# YTM32B1ME1 register map
Vendor: YTMicro; File version: 1.0
CPU: CM33 r0p4, little endian, MPU, FPU, 2 interrupt priority bits
Registers are 32-bit, read-write, reset 0x0 unless marked. A register's access mark holds for its fields unless they carry their own. Offsets are from the block's base; [hi:lo] are bit positions; lines under a group give offsets from that group; {n}, {i} and the like mark numbered series; 'fields as' and 'values as' point back to an identical list.

## CAN0 (part 2 of 4) — FlexCAN module
Base 0x400D0000; register names take the prefix CAN0_
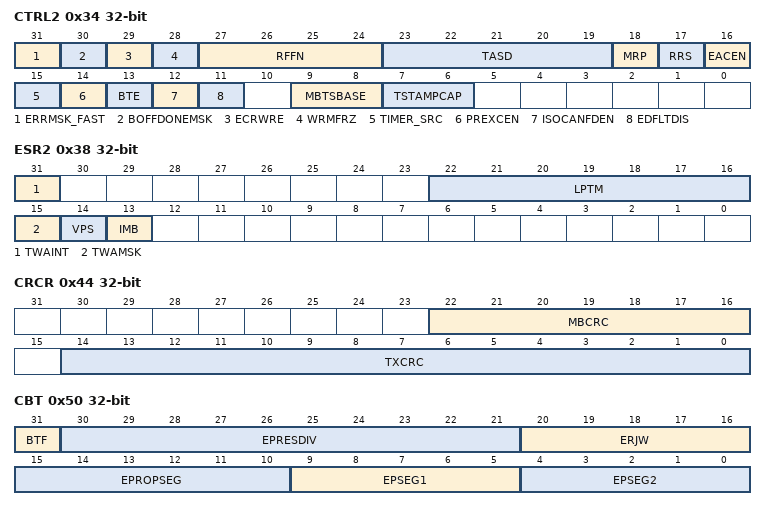
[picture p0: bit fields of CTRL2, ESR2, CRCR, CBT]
0x34 CTRL2
  [31] ERRMSK_FAST — ERRMSK_FAST provides a mask for the ERRINT_FAST Interrupt in CAN_ESR1. ERRMASK_FAST is not available (reserved, write 0) if parameter FD_EN is 0.
    0=ERRINT_FAST error interrupt disabled; 1=ERRINT_FAST error interrupt enabled
  [30] BOFFDONEMSK — Provides a mask for the Bus Off done interrupt in CAN_ESR1.
    0=Bus Off done interrupt disabled; 1=Bus Off done interrupt enabled
  [29] ECRWRE — ECRWRE is automatically set to 0 if the protocol described in section \hyperref[detection-and-correction-of-memory-errors]{"Detection and Correction of Memory Errors"} is not followed. ECRWRE is not available (reserved, write 0) if parameter ECC_EN is 0.
    0=Disable update; 1=Enable update
  [28] WRMFRZ — WRMFRZ can only be written in Freeze mode and has no effect out of Freeze mode. CAN_MCR.RFEN bit must not be set during FlexCAN memory initialization. WRMFRZ is not available (reserved, write 0) if parameter ECC_EN is 0.
    0=Maintain the write access restrictions; 1=Enable unrestricted write access to FlexCAN memory
  [27:24] RFFN — Number of Legacy Rx FIFO Filters – Defines the number of Legacy Rx FIFO filters. The maximum selectable number of filters is a function of configuration parameter NUMBER_OF_MB. RFFN must not be programmed with values that cause the number of message buffers occupied by Legacy Rx FIFO and ID Filter to exceed the number of mailboxes present, defined by CAN_MCR.MAXMB. Each group of eight filters occupies a memory space equivalent to two message buffers, which means that as more filters are implemented fewer mailboxes are available. Considering that the Legacy Rx FIFO occupies the memory space originally reserved for MB0–5, RFFN should be programmed with a value corresponding to a number of filters not greater than the number of available memory words, which can be calculated as follows: (SETUP_MB - 6) × 4 where SETUP_MB is the lower value between parameter NUMBER_OF_MB and register field CAN_MCR.MAXMB. The number of remaining mailboxes available will be: (SETUP_MB - 8) - (RFFN × 2) If the number of Legacy Rx FIFO filters programmed through RFFN exceeds the SETUP_MB value (memory space available), the exceeding ones will not be functional. NOTE: The number of the last remaining available mailbox is defined by the least value between (NUMBER_OF_MB - 1) and the CAN_MCR.MAXMB field. If Rx Individual Mask registers are not enabled, all Legacy Rx FIFO filters are affected by the Legacy Rx FIFO Global Mask. RFFN can only be written in Freeze mode as it is blocked by hardware in other modes.
  [23:19] TASD — TASD can be written only in Freeze mode because it is blocked by hardware in other modes. See \hyperref[tx-arbitration-start-delay]{"Tx Arbitration Start Delay"} for more details.
  [18] MRP — If MRP is set, the matching process starts from the mailboxes and if no match occurs the matching continues on the Legacy Rx FIFO. MRP can be written only in Freeze mode because it is blocked by hardware in other modes.
    0=Matching starts from Legacy Rx FIFO and continues on mailboxes; 1=Matching starts from mailboxes and continues on Legacy Rx FIFO
  [17] RRS — If RRS is asserted, a Remote Request Frame is submitted to a matching process and stored in the corresponding message buffer in the same fashion as a Data Frame. No automatic Remote Response Frame will be generated. If RRS is negated, the Remote Request Frame is submitted to a matching process and an automatic Remote Response Frame is generated if a message buffer with CODE=0b1010 is found with the same ID. RRS can be written only in Freeze mode because it is blocked by hardware in other modes.
    0=Remote Response Frame is generated; 1=Remote Request Frame is stored
  [16] EACEN — EACEN controls the comparison of IDE and RTR bits within Rx mailboxes filters with their corresponding bits in the incoming frame by the matching process. EACEN does not affect matching for Legacy Rx FIFO. EACEN can be written only in Freeze mode because it is blocked by hardware in other modes.
    0=Rx mailbox filter’s IDE bit is always compared and RTR is never compared, regardless of mask bits; 1=Enables the comparison of both the IDE and RTR bits of an Rx mailbox filter with the corresponding bits of the incoming frame. Mask bits do apply.
  [15] TIMER_SRC — TIMER_SRC can be written in Freeze mode only.
    0=The free-running timer is clocked by the CAN bit clock, which defines the baud rate on the CAN bus; 1=The free-running timer is clocked by an external time tick. The period can be either adjusted to be equal to the baud rate on the CAN bus or a different value as required.
  [14] PREXCEN — PREXCEN is writable only in Freeze mode. PREXCEN is not available (reserved, write 0) if parameter FE_EN is 0.
    0=Protocol exception is disabled; 1=Protocol exception is enabled
  [13] BTE — This field enables the use of the EPRS, EDCBT and ENCBT registers to configure the CAN bit timing segments, instead of using the bit timing fields of CBT, FDCBT, and CTRL1 registers. If CTRL2[BTE] is set: • PRESDIV, PROPSEG, PSEG1, PSEG2, and RJW fields in CTRL1 register are read as zero, and a write operation in them has no effect. • EPRESDIV, ERJW, EPROPSEG, EPSEG1, and EPSEG2 fields in the CBT register, and the FDCBT register, are read as zero and a write operation to them has no effect. • The ETDCOFF, ETDCEN, ETDCFAIL, and ETDCVAL fields of the ETDC register are used by FlexCAN instead of TDCOFF, TDCEN, TDCFAIL, and TDCVAL fields in FDCTRL register, which are read as zero, and a write operation in them has no effect. • ETDC[TDMDIS] can be used for disabling transceiver delay measurement.
    0=CAN Bit timing expansion is disabled; 1=CAN bit timing expansion is enabled
  [12] ISOCANFDEN — ISOCANFDEN enables ISO CAN FD compliant operation by enabling the following features, which are part of the ISO 11898 standard and not included in the original (Bosch) CAN FD protocol specification: • The count of variable stuff bits inserted from the Start of Frame bit to the last bit of Data field. Also, the modulo 8 count of variable stuff bits plus the respective parity bit (even parity calculated over the 3-bit modulo 8 count) are combined as the 4-bit Stuff Count field and inserted before the CRC Sequence field. • CRC calculation extends beyond the end of Data field and takes the Stuff Count field bits into account. ISOCANFDEN is writable only in Freeze mode. ISOCANFDEN is not available (reserved, write 0) if parameter FD_EN is 0.
    0=Disable ISO CAN FD specific features (non-ISO CAN FD operation); 1=Enable ISO CAN FD compliant operation
  [11] EDFLTDIS — When the edge filter is enabled, two consecutive nominal time quanta with dominant bus state are required to detect an edge that causes synchronization. When synchronization occurs, the counting of the sequence of eleven consecutive recessive bits is restarted. The edge filter prevents the dominant pulses that are shorter than a nominal bit time (present during the data phase of an FD Frame) from being mistaken for an idle condition. EDFLTDIS is writable only in Freeze mode. EDFLTDIS is not available (reserved, write 0) if parameter FD_EN is 0.
    0=Edge filter is enabled; 1=Edge filter is disabled
  [9:8] MBTSBASE — MBTSBASE selects which time base is used for capturing the 16-bit TIME STAMP field of the message buffer. MBTSBASE is writable only in Freeze mode. MBTSBASE is not available (reserved, write 0) if parameter TIME_STAMP_EN is 0.
    0=Message buffer time stamp base is CAN_TIMER; 1=Message buffer time stamp base is lower 16 bits of highresolution timer; 2=Message buffer time stamp base is upper 16 bits of high-resolution timer
  [7:6] TSTAMPCAP — TSTAMPCAP configures the point in time at which a 32-bit time base is captured during a CAN frame and stored in the highresolution time stamp register (CAN_HR_TIME_STAMPn). For Classical CAN frames, capture points can be the start of frame (SOF) bit or the point in time when a CAN frame is considered valid, which is the 7th bit of end of frame for transmission and the 6th bit of the end of frame for reception. For CAN FD frames, the high-resolution time stamp can be captured at SOF, the point in time when a CAN FD frame is considered valid, or the res bit. TSTAMPCAP is writable only in Freeze mode. TSTAMPCAP is not available (reserved, write 0) if parameter TIME_STAMP_EN is 0.
    0=The high-resolution time stamp capture is disabled; 1=The high-resolution time stamp is captured at the end of the CAN frame; 2=The high-resolution time stamp is captured at the start of the CAN frame; 3=The high-resolution time stamp is captured at the start of frame for classical CAN frames and at the res bit for CAN FD frames
0x38 ESR2 — The CAN_ESR2 register reports some general status information
  [31] TWAINT — TWAINT is set when the internal timer wraps around from 65535 to 0. If the corresponding mask bit (CAN_ESR2.TWAMSK) is set, an interrupt is generated to the CPU. TWAINT is cleared by writing 1 to it. Writing 0 has no effect. The TWAINT bit is not available (reserved, write 0) if parameter TIMER_WRAP_EN is 0.
    0=No such occurrence; 1=Timer wraparound has occurred
  [22:16] LPTM ro — If CAN_ESR2.VPS is asserted, LPTM indicates the lowest number inactive mailbox (see the CAN_ESR2.IMB bit description). If there is no inactive mailbox, then the mailbox indicated depends on the CAN_CTRL1.LBUF bit value: • If CAN_CTRL1.LBUF is negated, the mailbox indicated is the one that has the greatest arbitration value (see \hyperref[highest-priority-mailbox-first]{"Highest-Priority Mailbox First"} ). • If CAN_CTRL1.LBUF is asserted, the mailbox indicated is the highest number active Tx mailbox. If a Tx mailbox is being transmitted, it is not considered in LPTM calculation. If CAN_ESR2.IMB is not asserted and a frame is transmitted successfully, LPTM is updated with its mailbox number.
  [15] TWAMSK — Provides a mask for the Timer Wraparound interrupt (CAN_ESR2.TWAINT). The TWAMSK bit is not available (reserved, write 0) if parameter TIMER_WRAP_EN is 0.
    0=Timer Wraparound interrupt disabled; 1=Timer Wraparound interrupt enabled
  [14] VPS ro — VPS is asserted upon every complete Tx arbitration process unless the CPU writes to the C/S word of a mailbox that has already been scanned (is behind Tx Arbitration Pointer during the Tx arbitration process). If there is no inactive mailbox and only one Tx mailbox that is being transmitted, then VPS is not asserted. VPS is negated upon the start of every Tx arbitration process or upon a write to the C/S word of any mailbox. NOTE: VPS is not affected by any CPU write into the C/S of an MB that is blocked by the abort mechanism. When CAN_MCR.AEN is asserted, the abort code write into the C/S of an MB that is being transmitted (pending abort), or any write attempt into a Tx MB with CAN_IFLAG set is blocked.
    0=Contents of IMB and LPTM are invalid; 1=Contents of IMB and LPTM are valid
  [13] IMB ro — If CAN_ESR2.VPS is asserted, IMB indicates whether there is any inactive mailbox (CODE field is either 0b1000 or 0b0000). IMB is asserted in the following cases: • During arbitration, if a CAN_ESR2.LPTM is found and it is inactive. • If CAN_ESR2.IMB is not asserted and a frame is transmitted successfully. IMB is always cleared at start of arbitration (See \hyperref[arbitration-process]{"Arbitration Process"} ). NOTE: If an IMB is successfully transmitted and CAN_ESR2.IMB=0 (no inactive mailbox), then CAN_ESR2.VPS and CAN_ESR2.IMB are asserted and the index related to the MB just transmitted is loaded into CAN_ESR2.LPTM.
    0=If CAN_ESR2.VPS is asserted, CAN_ESR2.LPTM is not an inactive mailbox; 1=If CAN_ESR2.VPS is asserted, there is at least one inactive mailbox. CAN_ESR2.LPTM content is the number of the first one.
0x44 CRCR — The CAN_CRCR register provides information about the CRC of transmitted messages for non-FD messages. CAN_CRCR only reports the 15 low order bits of CRC calculations for messages in CAN FD format that require either 17 or 21 bits. For CAN FD format frames, the CAN_FDCRC register must be used. CAN_CRCR is updated at the same time the Tx interrupt flag is asserted. The CAN_FDCRC register is not available when parameter FD_EN is 0.
  [22:16] MBCRC ro — Indicates the number of the mailbox corresponding to the value in the CAN_CRCR.TXCRC field.
  [14:0] TXCRC ro — Indicates the CRC value of the last transmitted message for non-FD frames. For CAN FD frames, the CRC value is reported in CAN_FDCRC.
0x48 RXFGMASK
  [31:0] FGM — These bits mask the ID Filter Table elements bits in a perfect alignment. 0b - The corresponding bit in the filter is ``don't care". 1b - The corresponding bit in the filter is checked.
0x4C RXFIR — The CAN_RXFIR register provides information on the Legacy Rx FIFO. CAN_RXFIR is the port through which the CPU accesses the output of the RXFIR FIFO located in RAM. The RXFIR FIFO is written by the FlexCAN whenever a new message is moved into the Legacy Rx FIFO and its output is updated whenever the output of the Legacy Rx FIFO is updated with the next message. See \hyperref[legacy-rx-fifo]{"Legacy Rx FIFO"} for instructions on reading CAN_RXFIR.
  [8:0] IDHIT ro — Indicates which Identifier Acceptance Filter was hit by the received message that is in the output of the Legacy Rx FIFO. If multiple filters match the incoming message ID, the first matching IDAF found (lowest number) by the matching process is indicated. IDHIT is valid only when CAN_IFLAG1.BUF5I is asserted.
0x50 CBT — The CAN_CBT register is an alternative way to store the CAN bit timing variables described in the CAN_CTRL1 register. EPRESDIV, EPROPSEG, EPSEG1, EPSEG2, and ERJW are extended versions of CAN_CTRL1 register PRESDIV, PROPSEG, PSEG1, PSEG2, and RJW fields respectively. The BTF bit selects the use of the timing variables defined in CAN_CBT. The contents of CAN_CBT are not affected by soft reset. When CAN_CTRL2.BTE = 1, the EPRESDIV, ERJW, EPROPSEG, EPSEG1, and EPSEG2 fields in CAN_CBT are read as zero and a write operation to them has no effect. NOTE: The CAN bit variables in CAN_CTRL1 and in CAN_CBT are stored in the same register. NOTE: When the CAN FD feature is enabled (CAN_MCR.FDEN is set), always set $ ewline$ CAN_CBT.BTF.
  [31] BTF — BTF can be written in Freeze mode only.
    0=Extended bit time definitions disabled; 1=Extended bit time definitions enabled
  [30:21] EPRESDIV — When CAN_CBT.BTF is asserted, EPRESDIV defines the ratio between the PE clock frequency and the Serial Clock (Sclock) frequency. EPRESDIV extends the CAN_CTRL1.PRESDIV value range. Sclock frequency = PE clock frequency / (EPRESDIV + 1) The Sclock period defines the time quantum of the CAN protocol. For the reset value, the Sclock frequency is equal to the PE clock frequency (See \hyperref[protocol-timing]{"Protocol Timing"}). When CAN_CBT.BTF is negated, EPRESDIV has no effect. EPRESDIV can be written only in Freeze mode because it is blocked by hardware in other modes.
  [20:16] ERJW — When CAN_CBT.BTF is asserted, ERJW defines the maximum number of time quanta that a bit time can be changed by one resynchronization. ERJW extends the CAN_CTRL1.RJW value range. Resync Jump Width = ERJW + 1 One time quantum is equal to the Sclock period. When CAN_CBT.BTF is negated, ERJW has no effect. ERJW can be written only in Freeze mode because it is blocked by hardware in other modes.
  [15:10] EPROPSEG — When CAN_CBT.BTF is asserted, EPROPSEG defines the length of the Propagation Segment in the bit time. EPROPSEG extends the CAN_CTRL1.PROPSEG value range. Propagation Segment Time = (EPROPSEG + 1) × Time-Quanta Time-Quantum = one Sclock period When CAN_CBT.BTF is negated, EPROPSEG has no effect. EPROPSEG can be written only in Freeze mode because it is blocked by hardware in other modes.
  [9:5] EPSEG1 — When CAN_CBT.BTF is asserted, EPSEG1 defines the length of Phase Segment 1 in the bit time. EPSEG1 extends the CAN_CTRL1.PSEG1 value range. Phase Buffer Segment 1 = (EPSEG1 + 1) × Time-Quanta Time-Quantum = one Sclock period When CAN_CBT.BTF is negated, EPSEG1 has no effect. EPSEG1 can be written only in Freeze mode because it is blocked by hardware in other modes.
  [4:0] EPSEG2 — When CAN_CBT.BTF is asserted, EPSEG2 defines the length of Phase Segment 2 in the bit time. EPSEG2 extends the CAN_CTRL1.PSEG2 value range. Phase Buffer Segment 1 = (EPSEG2 + 1) × Time-Quanta Time-Quantum = one Sclock period When CAN_CBT.BTF is negated, EPSEG2 has no effect. EPSEG2 can be written only in Freeze mode because it is blocked by hardware in other modes.
0x68 IMASK4 — The CAN_IMASK4 register allows any number of the 32 message buffer interrupts to be enabled or disabled for MB127 to MB96. CAN_IMASK4 contains one interrupt mask bit per buffer, enabling the CPU to determine which buffer generates an interrupt after a successful transmission or reception (as indicated by the corresponding CAN_IFLAG4 bit). The CAN_IMASK4 register is not available if parameter NUMBER_OF_MB is less than 128.
  [31:0] BUF127TO96M — Each bit enables or disables the corresponding FlexCAN Message Buffer Interrupt for MB127 to MB96. When CAN FD is enabled, the MB range is defined according to the MBDSRn bit fields of the CAN_FDCTRL register. NOTE: Setting or clearing a bit in CAN_IMASK4 can assert or negate an interrupt request if the corresponding CAN_IFLAG4 bit is set. 0b - The corresponding buffer interrupt is disabled. 1b - The corresponding buffer interrupt is enabled.
0x6C IMASK3 — The CAN_IMASK3 register allows any number of the 32 message buffer interrupts to be enabled or disabled for MB95 to MB64. CAN_IMASK3 contains one interrupt mask bit per buffer, enabling the CPU to determine which buffer generates an interrupt after a successful transmission or reception (as indicated by the corresponding CAN_IFLAG3 bit). The CAN_IMASK3 register is not available if parameter NUMBER_OF_MB is less than 96.
  [31:0] BUF95TO64M — Each bit enables or disables the corresponding FlexCAN Message Buffer Interrupt for MB95 to MB64. When CAN FD is enabled, the MB range is defined according to the MBDSRn bit fields of the CAN_FDCTRL register. NOTE: Setting or clearing a bit in CAN_IMASK3 can assert or negate an interrupt request if the corresponding CAN_IFLAG3 bit is set. 0b - The corresponding buffer interrupt is disabled. 1b - The corresponding buffer interrupt is enabled.
0x70 IFLAG4 — The CAN_IFLAG4 register defines the flags for the 32 message buffer interrupts for MB127 to MB96. CAN_IFLAG4 contains one interrupt flag bit per buffer. Each successful transmission or reception sets the respective CAN_IFLAG4 bit. If the corresponding CAN_IMASK4 bit is set, an interrupt will be generated. The interrupt flag must be cleared by writing 1 to it. Writing 0 has no effect. Before updating the CAN_MCR.MAXMB field, the CPU must service the CAN_IFLAG4 bits whose MB value is greater than the CAN_MCR.MAXMB to be updated; otherwise, they will remain set and be inconsistent with the number of MBs available. The CAN_IFLAG4 register is not available if parameter NUMBER_OF_MB is less than 128.
  [31:0] BUF127TO96 — Each bit flags the corresponding FlexCAN Message Buffer Interrupt for MB127 to MB96. When CAN FD is enabled, the MB range is defined according to the MBDSRn bit fields of the CAN_FDCTRL register. 0b - The corresponding buffer has no occurrence of successfully completed transmission or reception. 1b - The corresponding buffer has successfully completed transmission or reception.
0x74 IFLAG3 — The CAN_IFLAG3 register defines the flags for the 32 Message Buffer interrupts for MB95 to MB64. CAN_IFLAG3 contains one interrupt flag bit per buffer. Each successful transmission or reception sets the respective CAN_IFLAG3 bit. If the corresponding CAN_IMASK3 bit is set, an interrupt will be generated. The interrupt flag must be cleared by writing 1 to it. Writing 0 has no effect. Before updating the CAN_MCR.MAXMB field, the CPU must service the CAN_IFLAG3 bits whose MB value is greater than the CAN_MCR.MAXMB to be updated; otherwise, they will remain set and be inconsistent with the number of MBs available. The CAN_IFLAG3 register is not available if parameter NUMBER_OF_MB is less than 96.
  [31:0] BUF95TO64 — Each bit flags the corresponding FlexCAN Message Buffer Interrupt for MB95 to MB64. When CAN FD is enabled, the MB range is defined according to the MBDSRn bit fields of the CAN_FDCTRL register. 0b - The corresponding buffer has no occurrence of successfully completed transmission or reception. 1b - The corresponding buffer has successfully completed transmission or reception.
{0x80+4i} RAM{i} (i=0..255)
  [31:0] RAM
0x880 RXIMR0 — The RX Individual Mask Registers are used to store the acceptance masks for ID filtering in Rx MBs and the Legacy Rx FIFO. When the Legacy Rx FIFO is disabled (CAN_MCR.RFEN is negated), an individual mask is provided for each available Rx mailbox on a one-to-one correspondence. When the Legacy Rx FIFO is enabled (CAN_MCR.RFEN is asserted), an individual mask is provided for each Legacy Rx FIFO ID Filter Table Element on a one-to-one correspondence depending on the setting of $ ewline$ CAN_CTRL2.RFFN (see \hyperref[legacy-rx-fifo]{"Legacy Rx FIFO"}). CAN_RXIMR0 stores the individual mask associated with either MB0 or ID Filter Table Element 0, CAN_RXIMR1 stores the individual mask associated with either MB1 or ID Filter Table Element 1, and so on. CAN_RXIMRn registers can only be accessed by the CPU when the FlexCAN is in Freeze mode; otherwise, they are blocked by hardware. The CAN_RXIMRn registers are not affected by reset. They are located in RAM and must be explicitly initialized prior to any reception. The CAN_RXIMRn registers are not available if parameter IRMQ_EN is 0.
  [31:0] MI — Each Individual Mask Bit masks the corresponding bit in both the mailbox filter and Legacy Rx FIFO ID Filter Table element in distinct ways. For mailbox filters, see the RXMGMASK register description. For Legacy Rx FIFO ID Filter Table elements, see the RXFGMASK register description. 0b - The corresponding bit in the filter is ``don't care". 1b - The corresponding bit in the filter is checked.
0x884 RXIMR1 — The RX Individual Mask Registers are used to store the acceptance masks for ID filtering in Rx MBs and the Legacy Rx FIFO. When the Legacy Rx FIFO is disabled (CAN_MCR.RFEN is negated), an individual mask is provided for each available Rx mailbox on a one-to-one correspondence. When the Legacy Rx FIFO is enabled (CAN_MCR.RFEN is asserted), an individual mask is provided for each Legacy Rx FIFO ID Filter Table Element on a one-to-one correspondence depending on the setting of $ ewline$ CAN_CTRL2.RFFN (see \hyperref[legacy-rx-fifo]{"Legacy Rx FIFO"}). CAN_RXIMR0 stores the individual mask associated with either MB0 or ID Filter Table Element 0, CAN_RXIMR1 stores the individual mask associated with either MB1 or ID Filter Table Element 1, and so on. CAN_RXIMRn registers can only be accessed by the CPU when the FlexCAN is in Freeze mode; otherwise, they are blocked by hardware. The CAN_RXIMRn registers are not affected by reset. They are located in RAM and must be explicitly initialized prior to any reception. The CAN_RXIMRn registers are not available if parameter IRMQ_EN is 0.
  fields as RXIMR0
0x888 RXIMR2 — The RX Individual Mask Registers are used to store the acceptance masks for ID filtering in Rx MBs and the Legacy Rx FIFO. When the Legacy Rx FIFO is disabled (CAN_MCR.RFEN is negated), an individual mask is provided for each available Rx mailbox on a one-to-one correspondence. When the Legacy Rx FIFO is enabled (CAN_MCR.RFEN is asserted), an individual mask is provided for each Legacy Rx FIFO ID Filter Table Element on a one-to-one correspondence depending on the setting of $ ewline$ CAN_CTRL2.RFFN (see \hyperref[legacy-rx-fifo]{"Legacy Rx FIFO"}). CAN_RXIMR0 stores the individual mask associated with either MB0 or ID Filter Table Element 0, CAN_RXIMR1 stores the individual mask associated with either MB1 or ID Filter Table Element 1, and so on. CAN_RXIMRn registers can only be accessed by the CPU when the FlexCAN is in Freeze mode; otherwise, they are blocked by hardware. The CAN_RXIMRn registers are not affected by reset. They are located in RAM and must be explicitly initialized prior to any reception. The CAN_RXIMRn registers are not available if parameter IRMQ_EN is 0.
  fields as RXIMR0
0x88C RXIMR3 — The RX Individual Mask Registers are used to store the acceptance masks for ID filtering in Rx MBs and the Legacy Rx FIFO. When the Legacy Rx FIFO is disabled (CAN_MCR.RFEN is negated), an individual mask is provided for each available Rx mailbox on a one-to-one correspondence. When the Legacy Rx FIFO is enabled (CAN_MCR.RFEN is asserted), an individual mask is provided for each Legacy Rx FIFO ID Filter Table Element on a one-to-one correspondence depending on the setting of $ ewline$ CAN_CTRL2.RFFN (see \hyperref[legacy-rx-fifo]{"Legacy Rx FIFO"}). CAN_RXIMR0 stores the individual mask associated with either MB0 or ID Filter Table Element 0, CAN_RXIMR1 stores the individual mask associated with either MB1 or ID Filter Table Element 1, and so on. CAN_RXIMRn registers can only be accessed by the CPU when the FlexCAN is in Freeze mode; otherwise, they are blocked by hardware. The CAN_RXIMRn registers are not affected by reset. They are located in RAM and must be explicitly initialized prior to any reception. The CAN_RXIMRn registers are not available if parameter IRMQ_EN is 0.
  fields as RXIMR0
0x890 RXIMR4 — The RX Individual Mask Registers are used to store the acceptance masks for ID filtering in Rx MBs and the Legacy Rx FIFO. When the Legacy Rx FIFO is disabled (CAN_MCR.RFEN is negated), an individual mask is provided for each available Rx mailbox on a one-to-one correspondence. When the Legacy Rx FIFO is enabled (CAN_MCR.RFEN is asserted), an individual mask is provided for each Legacy Rx FIFO ID Filter Table Element on a one-to-one correspondence depending on the setting of $ ewline$ CAN_CTRL2.RFFN (see \hyperref[legacy-rx-fifo]{"Legacy Rx FIFO"}). CAN_RXIMR0 stores the individual mask associated with either MB0 or ID Filter Table Element 0, CAN_RXIMR1 stores the individual mask associated with either MB1 or ID Filter Table Element 1, and so on. CAN_RXIMRn registers can only be accessed by the CPU when the FlexCAN is in Freeze mode; otherwise, they are blocked by hardware. The CAN_RXIMRn registers are not affected by reset. They are located in RAM and must be explicitly initialized prior to any reception. The CAN_RXIMRn registers are not available if parameter IRMQ_EN is 0.
  fields as RXIMR0
0x894 RXIMR5 — The RX Individual Mask Registers are used to store the acceptance masks for ID filtering in Rx MBs and the Legacy Rx FIFO. When the Legacy Rx FIFO is disabled (CAN_MCR.RFEN is negated), an individual mask is provided for each available Rx mailbox on a one-to-one correspondence. When the Legacy Rx FIFO is enabled (CAN_MCR.RFEN is asserted), an individual mask is provided for each Legacy Rx FIFO ID Filter Table Element on a one-to-one correspondence depending on the setting of $ ewline$ CAN_CTRL2.RFFN (see \hyperref[legacy-rx-fifo]{"Legacy Rx FIFO"}). CAN_RXIMR0 stores the individual mask associated with either MB0 or ID Filter Table Element 0, CAN_RXIMR1 stores the individual mask associated with either MB1 or ID Filter Table Element 1, and so on. CAN_RXIMRn registers can only be accessed by the CPU when the FlexCAN is in Freeze mode; otherwise, they are blocked by hardware. The CAN_RXIMRn registers are not affected by reset. They are located in RAM and must be explicitly initialized prior to any reception. The CAN_RXIMRn registers are not available if parameter IRMQ_EN is 0.
  fields as RXIMR0
0x898 RXIMR6 — The RX Individual Mask Registers are used to store the acceptance masks for ID filtering in Rx MBs and the Legacy Rx FIFO. When the Legacy Rx FIFO is disabled (CAN_MCR.RFEN is negated), an individual mask is provided for each available Rx mailbox on a one-to-one correspondence. When the Legacy Rx FIFO is enabled (CAN_MCR.RFEN is asserted), an individual mask is provided for each Legacy Rx FIFO ID Filter Table Element on a one-to-one correspondence depending on the setting of $ ewline$ CAN_CTRL2.RFFN (see \hyperref[legacy-rx-fifo]{"Legacy Rx FIFO"}). CAN_RXIMR0 stores the individual mask associated with either MB0 or ID Filter Table Element 0, CAN_RXIMR1 stores the individual mask associated with either MB1 or ID Filter Table Element 1, and so on. CAN_RXIMRn registers can only be accessed by the CPU when the FlexCAN is in Freeze mode; otherwise, they are blocked by hardware. The CAN_RXIMRn registers are not affected by reset. They are located in RAM and must be explicitly initialized prior to any reception. The CAN_RXIMRn registers are not available if parameter IRMQ_EN is 0.
  fields as RXIMR0
0x89C RXIMR7 — The RX Individual Mask Registers are used to store the acceptance masks for ID filtering in Rx MBs and the Legacy Rx FIFO. When the Legacy Rx FIFO is disabled (CAN_MCR.RFEN is negated), an individual mask is provided for each available Rx mailbox on a one-to-one correspondence. When the Legacy Rx FIFO is enabled (CAN_MCR.RFEN is asserted), an individual mask is provided for each Legacy Rx FIFO ID Filter Table Element on a one-to-one correspondence depending on the setting of $ ewline$ CAN_CTRL2.RFFN (see \hyperref[legacy-rx-fifo]{"Legacy Rx FIFO"}). CAN_RXIMR0 stores the individual mask associated with either MB0 or ID Filter Table Element 0, CAN_RXIMR1 stores the individual mask associated with either MB1 or ID Filter Table Element 1, and so on. CAN_RXIMRn registers can only be accessed by the CPU when the FlexCAN is in Freeze mode; otherwise, they are blocked by hardware. The CAN_RXIMRn registers are not affected by reset. They are located in RAM and must be explicitly initialized prior to any reception. The CAN_RXIMRn registers are not available if parameter IRMQ_EN is 0.
  fields as RXIMR0
0x8A0 RXIMR8 — The RX Individual Mask Registers are used to store the acceptance masks for ID filtering in Rx MBs and the Legacy Rx FIFO. When the Legacy Rx FIFO is disabled (CAN_MCR.RFEN is negated), an individual mask is provided for each available Rx mailbox on a one-to-one correspondence. When the Legacy Rx FIFO is enabled (CAN_MCR.RFEN is asserted), an individual mask is provided for each Legacy Rx FIFO ID Filter Table Element on a one-to-one correspondence depending on the setting of $ ewline$ CAN_CTRL2.RFFN (see \hyperref[legacy-rx-fifo]{"Legacy Rx FIFO"}). CAN_RXIMR0 stores the individual mask associated with either MB0 or ID Filter Table Element 0, CAN_RXIMR1 stores the individual mask associated with either MB1 or ID Filter Table Element 1, and so on. CAN_RXIMRn registers can only be accessed by the CPU when the FlexCAN is in Freeze mode; otherwise, they are blocked by hardware. The CAN_RXIMRn registers are not affected by reset. They are located in RAM and must be explicitly initialized prior to any reception. The CAN_RXIMRn registers are not available if parameter IRMQ_EN is 0.
  fields as RXIMR0
0x8A4 RXIMR9 — The RX Individual Mask Registers are used to store the acceptance masks for ID filtering in Rx MBs and the Legacy Rx FIFO. When the Legacy Rx FIFO is disabled (CAN_MCR.RFEN is negated), an individual mask is provided for each available Rx mailbox on a one-to-one correspondence. When the Legacy Rx FIFO is enabled (CAN_MCR.RFEN is asserted), an individual mask is provided for each Legacy Rx FIFO ID Filter Table Element on a one-to-one correspondence depending on the setting of $ ewline$ CAN_CTRL2.RFFN (see \hyperref[legacy-rx-fifo]{"Legacy Rx FIFO"}). CAN_RXIMR0 stores the individual mask associated with either MB0 or ID Filter Table Element 0, CAN_RXIMR1 stores the individual mask associated with either MB1 or ID Filter Table Element 1, and so on. CAN_RXIMRn registers can only be accessed by the CPU when the FlexCAN is in Freeze mode; otherwise, they are blocked by hardware. The CAN_RXIMRn registers are not affected by reset. They are located in RAM and must be explicitly initialized prior to any reception. The CAN_RXIMRn registers are not available if parameter IRMQ_EN is 0.
  fields as RXIMR0
0x8A8 RXIMR10 — The RX Individual Mask Registers are used to store the acceptance masks for ID filtering in Rx MBs and the Legacy Rx FIFO. When the Legacy Rx FIFO is disabled (CAN_MCR.RFEN is negated), an individual mask is provided for each available Rx mailbox on a one-to-one correspondence. When the Legacy Rx FIFO is enabled (CAN_MCR.RFEN is asserted), an individual mask is provided for each Legacy Rx FIFO ID Filter Table Element on a one-to-one correspondence depending on the setting of $ ewline$ CAN_CTRL2.RFFN (see \hyperref[legacy-rx-fifo]{"Legacy Rx FIFO"}). CAN_RXIMR0 stores the individual mask associated with either MB0 or ID Filter Table Element 0, CAN_RXIMR1 stores the individual mask associated with either MB1 or ID Filter Table Element 1, and so on. CAN_RXIMRn registers can only be accessed by the CPU when the FlexCAN is in Freeze mode; otherwise, they are blocked by hardware. The CAN_RXIMRn registers are not affected by reset. They are located in RAM and must be explicitly initialized prior to any reception. The CAN_RXIMRn registers are not available if parameter IRMQ_EN is 0.
  fields as RXIMR0
0x8AC RXIMR11 — The RX Individual Mask Registers are used to store the acceptance masks for ID filtering in Rx MBs and the Legacy Rx FIFO. When the Legacy Rx FIFO is disabled (CAN_MCR.RFEN is negated), an individual mask is provided for each available Rx mailbox on a one-to-one correspondence. When the Legacy Rx FIFO is enabled (CAN_MCR.RFEN is asserted), an individual mask is provided for each Legacy Rx FIFO ID Filter Table Element on a one-to-one correspondence depending on the setting of $ ewline$ CAN_CTRL2.RFFN (see \hyperref[legacy-rx-fifo]{"Legacy Rx FIFO"}). CAN_RXIMR0 stores the individual mask associated with either MB0 or ID Filter Table Element 0, CAN_RXIMR1 stores the individual mask associated with either MB1 or ID Filter Table Element 1, and so on. CAN_RXIMRn registers can only be accessed by the CPU when the FlexCAN is in Freeze mode; otherwise, they are blocked by hardware. The CAN_RXIMRn registers are not affected by reset. They are located in RAM and must be explicitly initialized prior to any reception. The CAN_RXIMRn registers are not available if parameter IRMQ_EN is 0.
  fields as RXIMR0
0x8B0 RXIMR12 — The RX Individual Mask Registers are used to store the acceptance masks for ID filtering in Rx MBs and the Legacy Rx FIFO. When the Legacy Rx FIFO is disabled (CAN_MCR.RFEN is negated), an individual mask is provided for each available Rx mailbox on a one-to-one correspondence. When the Legacy Rx FIFO is enabled (CAN_MCR.RFEN is asserted), an individual mask is provided for each Legacy Rx FIFO ID Filter Table Element on a one-to-one correspondence depending on the setting of $ ewline$ CAN_CTRL2.RFFN (see \hyperref[legacy-rx-fifo]{"Legacy Rx FIFO"}). CAN_RXIMR0 stores the individual mask associated with either MB0 or ID Filter Table Element 0, CAN_RXIMR1 stores the individual mask associated with either MB1 or ID Filter Table Element 1, and so on. CAN_RXIMRn registers can only be accessed by the CPU when the FlexCAN is in Freeze mode; otherwise, they are blocked by hardware. The CAN_RXIMRn registers are not affected by reset. They are located in RAM and must be explicitly initialized prior to any reception. The CAN_RXIMRn registers are not available if parameter IRMQ_EN is 0.
  fields as RXIMR0
0x8B4 RXIMR13 — The RX Individual Mask Registers are used to store the acceptance masks for ID filtering in Rx MBs and the Legacy Rx FIFO. When the Legacy Rx FIFO is disabled (CAN_MCR.RFEN is negated), an individual mask is provided for each available Rx mailbox on a one-to-one correspondence. When the Legacy Rx FIFO is enabled (CAN_MCR.RFEN is asserted), an individual mask is provided for each Legacy Rx FIFO ID Filter Table Element on a one-to-one correspondence depending on the setting of $ ewline$ CAN_CTRL2.RFFN (see \hyperref[legacy-rx-fifo]{"Legacy Rx FIFO"}). CAN_RXIMR0 stores the individual mask associated with either MB0 or ID Filter Table Element 0, CAN_RXIMR1 stores the individual mask associated with either MB1 or ID Filter Table Element 1, and so on. CAN_RXIMRn registers can only be accessed by the CPU when the FlexCAN is in Freeze mode; otherwise, they are blocked by hardware. The CAN_RXIMRn registers are not affected by reset. They are located in RAM and must be explicitly initialized prior to any reception. The CAN_RXIMRn registers are not available if parameter IRMQ_EN is 0.
  fields as RXIMR0
0x8B8 RXIMR14 — The RX Individual Mask Registers are used to store the acceptance masks for ID filtering in Rx MBs and the Legacy Rx FIFO. When the Legacy Rx FIFO is disabled (CAN_MCR.RFEN is negated), an individual mask is provided for each available Rx mailbox on a one-to-one correspondence. When the Legacy Rx FIFO is enabled (CAN_MCR.RFEN is asserted), an individual mask is provided for each Legacy Rx FIFO ID Filter Table Element on a one-to-one correspondence depending on the setting of $ ewline$ CAN_CTRL2.RFFN (see \hyperref[legacy-rx-fifo]{"Legacy Rx FIFO"}). CAN_RXIMR0 stores the individual mask associated with either MB0 or ID Filter Table Element 0, CAN_RXIMR1 stores the individual mask associated with either MB1 or ID Filter Table Element 1, and so on. CAN_RXIMRn registers can only be accessed by the CPU when the FlexCAN is in Freeze mode; otherwise, they are blocked by hardware. The CAN_RXIMRn registers are not affected by reset. They are located in RAM and must be explicitly initialized prior to any reception. The CAN_RXIMRn registers are not available if parameter IRMQ_EN is 0.
  fields as RXIMR0
0x8BC RXIMR15 — The RX Individual Mask Registers are used to store the acceptance masks for ID filtering in Rx MBs and the Legacy Rx FIFO. When the Legacy Rx FIFO is disabled (CAN_MCR.RFEN is negated), an individual mask is provided for each available Rx mailbox on a one-to-one correspondence. When the Legacy Rx FIFO is enabled (CAN_MCR.RFEN is asserted), an individual mask is provided for each Legacy Rx FIFO ID Filter Table Element on a one-to-one correspondence depending on the setting of $ ewline$ CAN_CTRL2.RFFN (see \hyperref[legacy-rx-fifo]{"Legacy Rx FIFO"}). CAN_RXIMR0 stores the individual mask associated with either MB0 or ID Filter Table Element 0, CAN_RXIMR1 stores the individual mask associated with either MB1 or ID Filter Table Element 1, and so on. CAN_RXIMRn registers can only be accessed by the CPU when the FlexCAN is in Freeze mode; otherwise, they are blocked by hardware. The CAN_RXIMRn registers are not affected by reset. They are located in RAM and must be explicitly initialized prior to any reception. The CAN_RXIMRn registers are not available if parameter IRMQ_EN is 0.
  fields as RXIMR0
0x8C0 RXIMR16 — The RX Individual Mask Registers are used to store the acceptance masks for ID filtering in Rx MBs and the Legacy Rx FIFO. When the Legacy Rx FIFO is disabled (CAN_MCR.RFEN is negated), an individual mask is provided for each available Rx mailbox on a one-to-one correspondence. When the Legacy Rx FIFO is enabled (CAN_MCR.RFEN is asserted), an individual mask is provided for each Legacy Rx FIFO ID Filter Table Element on a one-to-one correspondence depending on the setting of $ ewline$ CAN_CTRL2.RFFN (see \hyperref[legacy-rx-fifo]{"Legacy Rx FIFO"}). CAN_RXIMR0 stores the individual mask associated with either MB0 or ID Filter Table Element 0, CAN_RXIMR1 stores the individual mask associated with either MB1 or ID Filter Table Element 1, and so on. CAN_RXIMRn registers can only be accessed by the CPU when the FlexCAN is in Freeze mode; otherwise, they are blocked by hardware. The CAN_RXIMRn registers are not affected by reset. They are located in RAM and must be explicitly initialized prior to any reception. The CAN_RXIMRn registers are not available if parameter IRMQ_EN is 0.
  fields as RXIMR0
0x8C4 RXIMR17 — The RX Individual Mask Registers are used to store the acceptance masks for ID filtering in Rx MBs and the Legacy Rx FIFO. When the Legacy Rx FIFO is disabled (CAN_MCR.RFEN is negated), an individual mask is provided for each available Rx mailbox on a one-to-one correspondence. When the Legacy Rx FIFO is enabled (CAN_MCR.RFEN is asserted), an individual mask is provided for each Legacy Rx FIFO ID Filter Table Element on a one-to-one correspondence depending on the setting of $ ewline$ CAN_CTRL2.RFFN (see \hyperref[legacy-rx-fifo]{"Legacy Rx FIFO"}). CAN_RXIMR0 stores the individual mask associated with either MB0 or ID Filter Table Element 0, CAN_RXIMR1 stores the individual mask associated with either MB1 or ID Filter Table Element 1, and so on. CAN_RXIMRn registers can only be accessed by the CPU when the FlexCAN is in Freeze mode; otherwise, they are blocked by hardware. The CAN_RXIMRn registers are not affected by reset. They are located in RAM and must be explicitly initialized prior to any reception. The CAN_RXIMRn registers are not available if parameter IRMQ_EN is 0.
  fields as RXIMR0
0x8C8 RXIMR18 — The RX Individual Mask Registers are used to store the acceptance masks for ID filtering in Rx MBs and the Legacy Rx FIFO. When the Legacy Rx FIFO is disabled (CAN_MCR.RFEN is negated), an individual mask is provided for each available Rx mailbox on a one-to-one correspondence. When the Legacy Rx FIFO is enabled (CAN_MCR.RFEN is asserted), an individual mask is provided for each Legacy Rx FIFO ID Filter Table Element on a one-to-one correspondence depending on the setting of $ ewline$ CAN_CTRL2.RFFN (see \hyperref[legacy-rx-fifo]{"Legacy Rx FIFO"}). CAN_RXIMR0 stores the individual mask associated with either MB0 or ID Filter Table Element 0, CAN_RXIMR1 stores the individual mask associated with either MB1 or ID Filter Table Element 1, and so on. CAN_RXIMRn registers can only be accessed by the CPU when the FlexCAN is in Freeze mode; otherwise, they are blocked by hardware. The CAN_RXIMRn registers are not affected by reset. They are located in RAM and must be explicitly initialized prior to any reception. The CAN_RXIMRn registers are not available if parameter IRMQ_EN is 0.
  fields as RXIMR0
0x8CC RXIMR19 — The RX Individual Mask Registers are used to store the acceptance masks for ID filtering in Rx MBs and the Legacy Rx FIFO. When the Legacy Rx FIFO is disabled (CAN_MCR.RFEN is negated), an individual mask is provided for each available Rx mailbox on a one-to-one correspondence. When the Legacy Rx FIFO is enabled (CAN_MCR.RFEN is asserted), an individual mask is provided for each Legacy Rx FIFO ID Filter Table Element on a one-to-one correspondence depending on the setting of $ ewline$ CAN_CTRL2.RFFN (see \hyperref[legacy-rx-fifo]{"Legacy Rx FIFO"}). CAN_RXIMR0 stores the individual mask associated with either MB0 or ID Filter Table Element 0, CAN_RXIMR1 stores the individual mask associated with either MB1 or ID Filter Table Element 1, and so on. CAN_RXIMRn registers can only be accessed by the CPU when the FlexCAN is in Freeze mode; otherwise, they are blocked by hardware. The CAN_RXIMRn registers are not affected by reset. They are located in RAM and must be explicitly initialized prior to any reception. The CAN_RXIMRn registers are not available if parameter IRMQ_EN is 0.
  fields as RXIMR0
0x8D0 RXIMR20 — The RX Individual Mask Registers are used to store the acceptance masks for ID filtering in Rx MBs and the Legacy Rx FIFO. When the Legacy Rx FIFO is disabled (CAN_MCR.RFEN is negated), an individual mask is provided for each available Rx mailbox on a one-to-one correspondence. When the Legacy Rx FIFO is enabled (CAN_MCR.RFEN is asserted), an individual mask is provided for each Legacy Rx FIFO ID Filter Table Element on a one-to-one correspondence depending on the setting of $ ewline$ CAN_CTRL2.RFFN (see \hyperref[legacy-rx-fifo]{"Legacy Rx FIFO"}). CAN_RXIMR0 stores the individual mask associated with either MB0 or ID Filter Table Element 0, CAN_RXIMR1 stores the individual mask associated with either MB1 or ID Filter Table Element 1, and so on. CAN_RXIMRn registers can only be accessed by the CPU when the FlexCAN is in Freeze mode; otherwise, they are blocked by hardware. The CAN_RXIMRn registers are not affected by reset. They are located in RAM and must be explicitly initialized prior to any reception. The CAN_RXIMRn registers are not available if parameter IRMQ_EN is 0.
  fields as RXIMR0
0x8D4 RXIMR21 — The RX Individual Mask Registers are used to store the acceptance masks for ID filtering in Rx MBs and the Legacy Rx FIFO. When the Legacy Rx FIFO is disabled (CAN_MCR.RFEN is negated), an individual mask is provided for each available Rx mailbox on a one-to-one correspondence. When the Legacy Rx FIFO is enabled (CAN_MCR.RFEN is asserted), an individual mask is provided for each Legacy Rx FIFO ID Filter Table Element on a one-to-one correspondence depending on the setting of $ ewline$ CAN_CTRL2.RFFN (see \hyperref[legacy-rx-fifo]{"Legacy Rx FIFO"}). CAN_RXIMR0 stores the individual mask associated with either MB0 or ID Filter Table Element 0, CAN_RXIMR1 stores the individual mask associated with either MB1 or ID Filter Table Element 1, and so on. CAN_RXIMRn registers can only be accessed by the CPU when the FlexCAN is in Freeze mode; otherwise, they are blocked by hardware. The CAN_RXIMRn registers are not affected by reset. They are located in RAM and must be explicitly initialized prior to any reception. The CAN_RXIMRn registers are not available if parameter IRMQ_EN is 0.
  fields as RXIMR0

## CAN1 (part 2 of 4) — FlexCAN module
Base 0x400D4000; register names take the prefix CAN1_
Registers as CAN0.

## CAN2 (part 2 of 4) — FlexCAN module
Base 0x400D8000; register names take the prefix CAN2_
Registers as CAN0.

## CAN3 (part 2 of 4) — FlexCAN module
Base 0x400DC000; register names take the prefix CAN3_
Registers as CAN0.
